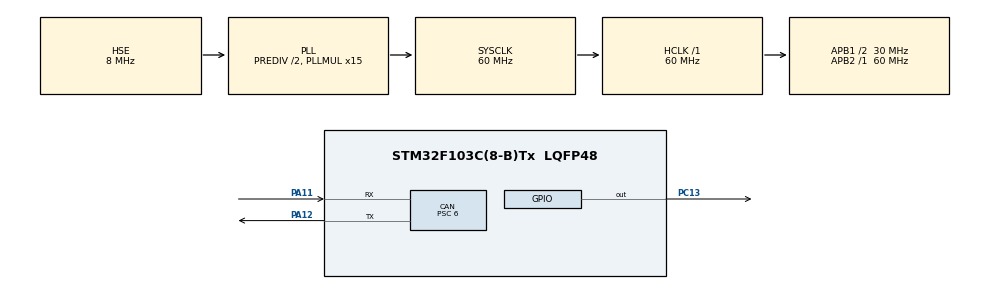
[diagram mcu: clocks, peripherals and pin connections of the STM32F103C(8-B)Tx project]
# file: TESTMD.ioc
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CAN.BS1=CAN_BS1_2TQ
CAN.BS2=CAN_BS2_2TQ
CAN.CalculateBaudRate=1000000
CAN.CalculateTimeBit=1000
CAN.CalculateTimeQuantum=200.0
CAN.Mode=CAN_MODE_SILENT_LOOPBACK
CAN.Prescaler=6
Mcu.Family=STM32F1
Mcu.Name=STM32F103C(8-B)Tx
Mcu.Package=LQFP48
NVIC.CAN1_RX1_IRQn=true\:0\:0\:false\:false\:true\:true\:true\:true
NVIC.PriorityGroup=NVIC_PRIORITYGROUP_4
NVIC.USB_LP_CAN1_RX0_IRQn=true\:0\:0\:false\:false\:true\:true\:true\:true
PA11.Mode=CAN_Activate
PA11.Signal=CAN_RX
PA12.Mode=CAN_Activate
PA12.Signal=CAN_TX
PA13.Mode=Serial_Wire
PA13.Signal=SYS_JTMS-SWDIO
PA14.Mode=Serial_Wire
PA14.Signal=SYS_JTCK-SWCLK
PC13-TAMPER-RTC.GPIO_ModeDefaultOutputPP=GPIO_MODE_OUTPUT_OD
PC13-TAMPER-RTC.GPIO_PuPd=GPIO_NOPULL
PC13-TAMPER-RTC.PinState=GPIO_PIN_SET
PC13-TAMPER-RTC.Signal=GPIO_Output
PD0-OSC_IN.Mode=HSE-External-Oscillator
PD0-OSC_IN.Signal=RCC_OSC_IN
PD1-OSC_OUT.Mode=HSE-External-Oscillator
PD1-OSC_OUT.Signal=RCC_OSC_OUT
ProjectManager.HeapSize=0x200
ProjectManager.StackSize=0x400
ProjectManager.TargetToolchain=CMake
RCC.AHBFreq_Value=60000000
RCC.APB1CLKDivider=RCC_HCLK_DIV2
RCC.APB1Freq_Value=30000000
RCC.APB1TimFreq_Value=60000000
RCC.APB2Freq_Value=60000000
RCC.APB2TimFreq_Value=60000000
RCC.HCLKFreq_Value=60000000
RCC.HSEDivPLL=RCC_HSE_PREDIV_DIV2
RCC.PLLMUL=RCC_PLL_MUL15
RCC.PLLSourceVirtual=RCC_PLLSOURCE_HSE
RCC.SYSCLKFreq_VALUE=60000000
RCC.SYSCLKSource=RCC_SYSCLKSOURCE_PLLCLK
RCC.USBFreq_Value=60000000
board=custom

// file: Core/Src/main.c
/* USER CODE BEGIN Header */
/**
  ******************************************************************************
  * @file           : main.c
  * @brief          : Main program body
  ******************************************************************************
  * @attention
  *
  * Copyright (c) 2026 STMicroelectronics.
  * All rights reserved.
  *
  * This software is licensed under terms that can be found in the LICENSE file
  * in the root directory of this software component.
  * If no LICENSE file comes with this software, it is provided AS-IS.
  *
  ******************************************************************************
  */
/* USER CODE END Header */
#include "main.h"
#include "can.h"
#include "gpio.h"

/* USER CODE BEGIN PM */
//滤波器编号
#define CAN_FILTER(x) ((x) <<3)
//FIFO选择
#define CAN_FIFO_0 (0 <<2)
#define CAN_FIFO_1 (1 <<2)
//标准帧标志
#define CAN_STDID (0 <<1)
#define CAN_EXTID (1 <<1)
//数据帧标志
#define CAN_DATA_TYPE (0 <<0)
#define CAN_REMOTE_TYPE (1 <<0)
/* USER CODE END PM */

void SystemClock_Config(void);

/* USER CODE BEGIN 0 */
//初始化CAN模块
void CAN_Init(CAN_HandleTypeDef *hcan) {
  HAL_CAN_Start(hcan);//开启CAN通信
  __HAL_CAN_ENABLE_IT(hcan,CAN_IT_RX_FIFO0_MSG_PENDING);
  __HAL_CAN_ENABLE_IT(hcan,CAN_IT_RX_FIFO1_MSG_PENDING);//开启FIFO接收中断

}

void CAN_Filter_Mask_Config(CAN_HandleTypeDef *hcan, uint8_t Object_Para,uint32_t IDA,uint32_t MaskA,uint32_t IDB,uint32_t MaskB) {
  CAN_FilterTypeDef CAN_Filter_InitStruct;

  CAN_Filter_InitStruct.FilterIdLow = (IDA & 0x7FF) << 5;
  CAN_Filter_InitStruct.FilterIdHigh = (IDB & 0x7FF) << 5;
  CAN_Filter_InitStruct.FilterMaskIdLow = (MaskA & 0x7FF) << 5;
  CAN_Filter_InitStruct.FilterMaskIdHigh = (MaskB & 0x7FF) << 5;

  //滤波器序号
  CAN_Filter_InitStruct.FilterBank = (Object_Para >> 3) & 0x1F;
  //滤波器模式
  CAN_Filter_InitStruct.FilterMode = CAN_FILTERMODE_IDMASK;
  //32位滤波
  CAN_Filter_InitStruct.FilterScale = CAN_FILTERSCALE_16BIT;
  //使能滤波器
  CAN_Filter_InitStruct.FilterActivation = ENABLE;
  //滤波器绑定FIFO
  CAN_Filter_InitStruct.FilterFIFOAssignment = (Object_Para >> 2) & 0x01;
  HAL_CAN_ConfigFilter(hcan, &CAN_Filter_InitStruct);
}

uint8_t CAN_Transmit(CAN_HandleTypeDef *hcan, uint16_t ID, uint8_t *Data,uint16_t Length) {
  CAN_TxHeaderTypeDef TxHeader;
  uint32_t TxMailbox;

  TxHeader.StdId =ID;
  TxHeader.DLC = Length;
  TxHeader.IDE = 0;
  TxHeader.RTR = 0;
  TxHeader.ExtId = 0;

  return    (HAL_CAN_AddTxMessage(hcan, &TxHeader, Data, &TxMailbox));

}

void LED_Control(uint8_t Data) {

  if (Data%2 ==1) {
    HAL_GPIO_WritePin(GPIOC,GPIO_PIN_13,GPIO_PIN_RESET);
  }
else {
  HAL_GPIO_WritePin(GPIOC,GPIO_PIN_13,GPIO_PIN_SET);
}
}

void HAL_CAN_RxFifo1MsgPendingCallback(CAN_HandleTypeDef *hcan)
{
  CAN_RxHeaderTypeDef RxHeader;
  uint8_t Data = 0;
  HAL_CAN_GetRxMessage(hcan, CAN_RX_FIFO1, &RxHeader, &Data);

    LED_Control(Data);

}

/* USER CODE END 0 */

int main(void)
{

  /* MCU Configuration--------------------------------------------------------*/

  /* Reset of all peripherals, Initializes the Flash interface and the Systick. */
  HAL_Init();

  /* Configure the system clock */
  SystemClock_Config();

  /* Initialize all configured peripherals */
  MX_GPIO_Init();
  MX_CAN_Init();
  /* USER CODE BEGIN 2 */

  uint8_t Send_Data = 0;
  CAN_Init(&hcan);
  CAN_Filter_Mask_Config(&hcan,CAN_FILTER(13)|CAN_FIFO_1|CAN_STDID|CAN_DATA_TYPE,0x114,0x7ff,0x200,0x7ff);

  /* USER CODE END 2 */

  /* Infinite loop */
  /* USER CODE BEGIN WHILE */
  while (1)
  {

    Send_Data++;
    CAN_Transmit(&hcan,0x200,&Send_Data,1);
    /* USER CODE END WHILE */

    /* USER CODE BEGIN 3 */
    HAL_Delay(300);
  }
  /* USER CODE END 3 */
}

void SystemClock_Config(void)
{
  RCC_OscInitTypeDef RCC_OscInitStruct = {0};
  RCC_ClkInitTypeDef RCC_ClkInitStruct = {0};

  /** Initializes the RCC Oscillators according to the specified parameters
  * in the RCC_OscInitTypeDef structure.
  */
  RCC_OscInitStruct.OscillatorType = RCC_OSCILLATORTYPE_HSE;
  RCC_OscInitStruct.HSEState = RCC_HSE_ON;
  RCC_OscInitStruct.HSEPredivValue = RCC_HSE_PREDIV_DIV2;
  RCC_OscInitStruct.HSIState = RCC_HSI_ON;
  RCC_OscInitStruct.PLL.PLLState = RCC_PLL_ON;
  RCC_OscInitStruct.PLL.PLLSource = RCC_PLLSOURCE_HSE;
  RCC_OscInitStruct.PLL.PLLMUL = RCC_PLL_MUL15;
  if (HAL_RCC_OscConfig(&RCC_OscInitStruct) != HAL_OK)
  {
    Error_Handler();
  }

  /** Initializes the CPU, AHB and APB buses clocks
  */
  RCC_ClkInitStruct.ClockType = RCC_CLOCKTYPE_HCLK|RCC_CLOCKTYPE_SYSCLK
                              |RCC_CLOCKTYPE_PCLK1|RCC_CLOCKTYPE_PCLK2;
  RCC_ClkInitStruct.SYSCLKSource = RCC_SYSCLKSOURCE_PLLCLK;
  RCC_ClkInitStruct.AHBCLKDivider = RCC_SYSCLK_DIV1;
  RCC_ClkInitStruct.APB1CLKDivider = RCC_HCLK_DIV2;
  RCC_ClkInitStruct.APB2CLKDivider = RCC_HCLK_DIV1;

  if (HAL_RCC_ClockConfig(&RCC_ClkInitStruct, FLASH_LATENCY_2) != HAL_OK)
  {
    Error_Handler();
  }
}

void Error_Handler(void)
{
  __disable_irq();
  while (1)
  {
  }
}
